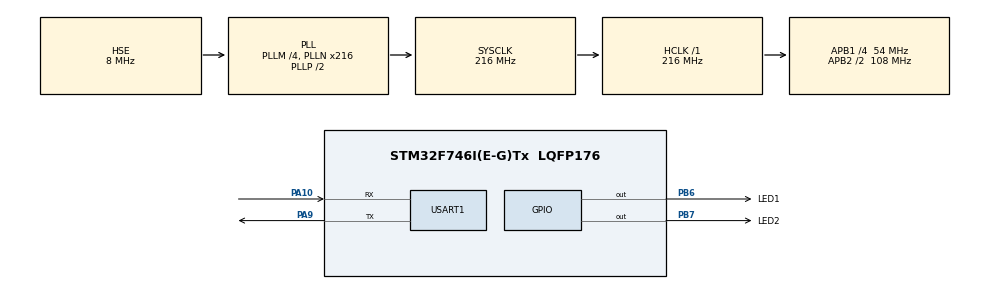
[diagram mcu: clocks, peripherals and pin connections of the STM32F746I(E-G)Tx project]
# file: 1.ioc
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FREERTOS.Tasks01=defaultTask,0,128,StartDefaultTask,Default
Mcu.Family=STM32F7
Mcu.Name=STM32F746I(E-G)Tx
Mcu.Package=LQFP176
NVIC.PriorityGroup=NVIC_PRIORITYGROUP_4
NVIC.TIM2_IRQn=true\:0\:0\:false
NVIC.TimeBase=TIM2_IRQn
NVIC.TimeBaseIP=TIM2
PA10.Mode=Asynchronous
PA10.Signal=USART1_RX
PA9.Mode=Asynchronous
PA9.Signal=USART1_TX
PB6.GPIO_Label=LED1
PB6.Signal=GPIO_Output
PB7.GPIO_Label=LED2
PB7.Signal=GPIO_Output
PH0/OSC_IN.Mode=HSE-External-Oscillator
PH0/OSC_IN.Signal=RCC_OSC_IN
PH1/OSC_OUT.Mode=HSE-External-Oscillator
PH1/OSC_OUT.Signal=RCC_OSC_OUT
ProjectManager.HeapSize=0x400
ProjectManager.StackSize=0x200
ProjectManager.TargetToolchain=TrueSTUDIO
RCC.AHBFreq_Value=216000000
RCC.APB1CLKDivider=RCC_HCLK_DIV4
RCC.APB1Freq_Value=54000000
RCC.APB1TimFreq_Value=108000000
RCC.APB2CLKDivider=RCC_HCLK_DIV2
RCC.APB2Freq_Value=108000000
RCC.APB2TimFreq_Value=216000000
RCC.CortexFreq_Value=216000000
RCC.HCLKFreq_Value=216000000
RCC.HSE_VALUE=8000000
RCC.HSI_VALUE=16000000
RCC.LSE_VALUE=32768
RCC.PLLM=4
RCC.PLLN=216
RCC.PLLSourceVirtual=RCC_PLLSOURCE_HSE
RCC.SYSCLKFreq_VALUE=216000000
RCC.SYSCLKSource=RCC_SYSCLKSOURCE_PLLCLK
RCC.USBFreq_Value=216000000
RCC.VCOOutputFreq_Value=432000000
USART1.WordLength=UART_WORDLENGTH_8B
VP_FREERTOS_VS_ENABLE.Mode=Enabled
VP_SYS_VS_tim2.Mode=TIM2
board=1

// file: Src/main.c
/**
  ******************************************************************************
  * File Name          : main.c
  * Description        : Main program body
  ******************************************************************************
  *
  * COPYRIGHT(c) 2016 STMicroelectronics
  *
  * Redistribution and use in source and binary forms, with or without modification,
  * are permitted provided that the following conditions are met:
  *   1. Redistributions of source code must retain the above copyright notice,
  *      this list of conditions and the following disclaimer.
  *   2. Redistributions in binary form must reproduce the above copyright notice,
  *      this list of conditions and the following disclaimer in the documentation
  *      and/or other materials provided with the distribution.
  *   3. Neither the name of STMicroelectronics nor the names of its contributors
  *      may be used to endorse or promote products derived from this software
  *      without specific prior written permission.
  *
  * THIS SOFTWARE IS PROVIDED BY THE COPYRIGHT HOLDERS AND CONTRIBUTORS "AS IS"
  * AND ANY EXPRESS OR IMPLIED WARRANTIES, INCLUDING, BUT NOT LIMITED TO, THE
  * IMPLIED WARRANTIES OF MERCHANTABILITY AND FITNESS FOR A PARTICULAR PURPOSE ARE
  * DISCLAIMED. IN NO EVENT SHALL THE COPYRIGHT HOLDER OR CONTRIBUTORS BE LIABLE
  * FOR ANY DIRECT, INDIRECT, INCIDENTAL, SPECIAL, EXEMPLARY, OR CONSEQUENTIAL
  * DAMAGES (INCLUDING, BUT NOT LIMITED TO, PROCUREMENT OF SUBSTITUTE GOODS OR
  * SERVICES; LOSS OF USE, DATA, OR PROFITS; OR BUSINESS INTERRUPTION) HOWEVER
  * CAUSED AND ON ANY THEORY OF LIABILITY, WHETHER IN CONTRACT, STRICT LIABILITY,
  * OR TORT (INCLUDING NEGLIGENCE OR OTHERWISE) ARISING IN ANY WAY OUT OF THE USE
  * OF THIS SOFTWARE, EVEN IF ADVISED OF THE POSSIBILITY OF SUCH DAMAGE.
  *
  ******************************************************************************
  */
#include "stm32f7xx_hal.h"
#include "cmsis_os.h"
#include "usart.h"
#include "gpio.h"

/* USER CODE BEGIN PV */
/* Private variables ---------------------------------------------------------*/

/* USER CODE END PV */

void SystemClock_Config(void);
void MX_FREERTOS_Init(void);

/* USER CODE BEGIN PFP */
/* Private function prototypes -----------------------------------------------*/

/* USER CODE END PFP */

int main(void)
{

  /* MCU Configuration----------------------------------------------------------*/

  /* Reset of all peripherals, Initializes the Flash interface and the Systick. */
  HAL_Init();

  /* Configure the system clock */
  SystemClock_Config();

  /* Initialize all configured peripherals */
  MX_GPIO_Init();
  MX_USART1_UART_Init();

  /* Call init function for freertos objects (in freertos.c) */
  MX_FREERTOS_Init();

  /* Start scheduler */
  osKernelStart();

  /* We should never get here as control is now taken by the scheduler */

  /* Infinite loop */
  while (1)
  {

  }

}

/** System Clock Configuration
*/
void SystemClock_Config(void)
{

  RCC_OscInitTypeDef RCC_OscInitStruct;
  RCC_ClkInitTypeDef RCC_ClkInitStruct;
  RCC_PeriphCLKInitTypeDef PeriphClkInitStruct;

  __PWR_CLK_ENABLE();

  __HAL_PWR_VOLTAGESCALING_CONFIG(PWR_REGULATOR_VOLTAGE_SCALE1);

  RCC_OscInitStruct.OscillatorType = RCC_OSCILLATORTYPE_HSE;
  RCC_OscInitStruct.HSEState = RCC_HSE_ON;
  RCC_OscInitStruct.PLL.PLLState = RCC_PLL_ON;
  RCC_OscInitStruct.PLL.PLLSource = RCC_PLLSOURCE_HSE;
  RCC_OscInitStruct.PLL.PLLM = 4;
  RCC_OscInitStruct.PLL.PLLN = 216;
  RCC_OscInitStruct.PLL.PLLP = RCC_PLLP_DIV2;
  RCC_OscInitStruct.PLL.PLLQ = 2;
  HAL_RCC_OscConfig(&RCC_OscInitStruct);

  HAL_PWREx_ActivateOverDrive();

  RCC_ClkInitStruct.ClockType = RCC_CLOCKTYPE_HCLK|RCC_CLOCKTYPE_SYSCLK
                              |RCC_CLOCKTYPE_PCLK1|RCC_CLOCKTYPE_PCLK2;
  RCC_ClkInitStruct.SYSCLKSource = RCC_SYSCLKSOURCE_PLLCLK;
  RCC_ClkInitStruct.AHBCLKDivider = RCC_SYSCLK_DIV1;
  RCC_ClkInitStruct.APB1CLKDivider = RCC_HCLK_DIV4;
  RCC_ClkInitStruct.APB2CLKDivider = RCC_HCLK_DIV2;
  HAL_RCC_ClockConfig(&RCC_ClkInitStruct, FLASH_LATENCY_7);

  PeriphClkInitStruct.PeriphClockSelection = RCC_PERIPHCLK_USART1;
  PeriphClkInitStruct.Usart1ClockSelection = RCC_USART1CLKSOURCE_PCLK2;
  HAL_RCCEx_PeriphCLKConfig(&PeriphClkInitStruct);

  HAL_SYSTICK_Config(HAL_RCC_GetHCLKFreq()/1000);

  HAL_SYSTICK_CLKSourceConfig(SYSTICK_CLKSOURCE_HCLK);

  /* SysTick_IRQn interrupt configuration */
  HAL_NVIC_SetPriority(SysTick_IRQn, 15, 0);
}

/************************ (C) COPYRIGHT STMicroelectronics *****END OF FILE****/

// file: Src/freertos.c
/**
  ******************************************************************************
  * File Name          : freertos.c
  * Description        : Code for freertos applications
  ******************************************************************************
  *
  * COPYRIGHT(c) 2016 STMicroelectronics
  *
  * Redistribution and use in source and binary forms, with or without modification,
  * are permitted provided that the following conditions are met:
  *   1. Redistributions of source code must retain the above copyright notice,
  *      this list of conditions and the following disclaimer.
  *   2. Redistributions in binary form must reproduce the above copyright notice,
  *      this list of conditions and the following disclaimer in the documentation
  *      and/or other materials provided with the distribution.
  *   3. Neither the name of STMicroelectronics nor the names of its contributors
  *      may be used to endorse or promote products derived from this software
  *      without specific prior written permission.
  *
  * THIS SOFTWARE IS PROVIDED BY THE COPYRIGHT HOLDERS AND CONTRIBUTORS "AS IS"
  * AND ANY EXPRESS OR IMPLIED WARRANTIES, INCLUDING, BUT NOT LIMITED TO, THE
  * IMPLIED WARRANTIES OF MERCHANTABILITY AND FITNESS FOR A PARTICULAR PURPOSE ARE
  * DISCLAIMED. IN NO EVENT SHALL THE COPYRIGHT HOLDER OR CONTRIBUTORS BE LIABLE
  * FOR ANY DIRECT, INDIRECT, INCIDENTAL, SPECIAL, EXEMPLARY, OR CONSEQUENTIAL
  * DAMAGES (INCLUDING, BUT NOT LIMITED TO, PROCUREMENT OF SUBSTITUTE GOODS OR
  * SERVICES; LOSS OF USE, DATA, OR PROFITS; OR BUSINESS INTERRUPTION) HOWEVER
  * CAUSED AND ON ANY THEORY OF LIABILITY, WHETHER IN CONTRACT, STRICT LIABILITY,
  * OR TORT (INCLUDING NEGLIGENCE OR OTHERWISE) ARISING IN ANY WAY OUT OF THE USE
  * OF THIS SOFTWARE, EVEN IF ADVISED OF THE POSSIBILITY OF SUCH DAMAGE.
  *
  ******************************************************************************
  */

#include "FreeRTOS.h"
#include "task.h"
#include "cmsis_os.h"

/* USER CODE BEGIN Includes */
#include "gpio.h"
#include "usart.h"

/* USER CODE END Includes */

osThreadId defaultTaskHandle;

void StartDefaultTask(void const * argument);

void MX_FREERTOS_Init(void); /* (MISRA C 2004 rule 8.1) */

/* Hook prototypes */

/* Init FreeRTOS */

void MX_FREERTOS_Init(void) {

  /* Create the thread(s) */
  /* definition and creation of defaultTask */
  osThreadDef(defaultTask, StartDefaultTask, osPriorityNormal, 0, 128);
  defaultTaskHandle = osThreadCreate(osThread(defaultTask), NULL);

}

/* StartDefaultTask function */
void StartDefaultTask(void const * argument)
{

  /* USER CODE BEGIN StartDefaultTask */
  /* Infinite loop */
  for(;;)
  {
	  osDelay(1000);
	  HAL_GPIO_TogglePin(GPIOB, LED1_Pin | LED2_Pin);
	  info_upload("test!!!");

  }
  /* USER CODE END StartDefaultTask */
}

/************************ (C) COPYRIGHT STMicroelectronics *****END OF FILE****/
